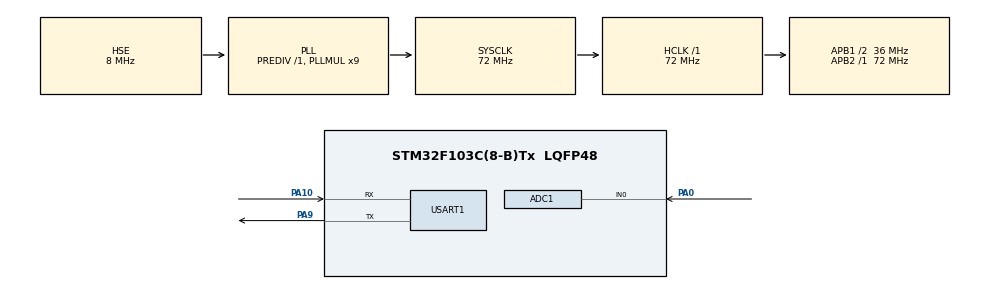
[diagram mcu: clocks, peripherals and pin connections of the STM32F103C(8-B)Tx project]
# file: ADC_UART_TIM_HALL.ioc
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ADC1.Channel-1\#ChannelRegularConversion=ADC_CHANNEL_0
ADC1.ExternalTrigConv=ADC_EXTERNALTRIGCONV_T1_CC1
ADC1.NbrOfConversionFlag=1
ADC1.Rank-1\#ChannelRegularConversion=1
ADC1.SamplingTime-1\#ChannelRegularConversion=ADC_SAMPLETIME_1CYCLE_5
ADC1.master=1
Mcu.Family=STM32F1
Mcu.Name=STM32F103C(8-B)Tx
Mcu.Package=LQFP48
NVIC.ADC1_2_IRQn=true\:0\:0\:false\:false\:true\:true\:true
NVIC.PriorityGroup=NVIC_PRIORITYGROUP_4
NVIC.TIM1_UP_IRQn=true\:0\:0\:false\:false\:true\:true\:true
NVIC.USART1_IRQn=true\:0\:0\:false\:false\:true\:true\:true
PA0-WKUP.Signal=ADCx_IN0
PA10.Mode=Asynchronous
PA10.Signal=USART1_RX
PA13.Mode=Serial_Wire
PA13.Signal=SYS_JTMS-SWDIO
PA14.Mode=Serial_Wire
PA14.Signal=SYS_JTCK-SWCLK
PA9.Mode=Asynchronous
PA9.Signal=USART1_TX
PD0-OSC_IN.Mode=HSE-External-Oscillator
PD0-OSC_IN.Signal=RCC_OSC_IN
PD1-OSC_OUT.Mode=HSE-External-Oscillator
PD1-OSC_OUT.Signal=RCC_OSC_OUT
ProjectManager.HeapSize=0x200
ProjectManager.StackSize=0x400
ProjectManager.TargetToolchain=STM32CubeIDE
RCC.ADCPresc=RCC_ADCPCLK2_DIV6
RCC.AHBFreq_Value=72000000
RCC.APB1CLKDivider=RCC_HCLK_DIV2
RCC.APB1Freq_Value=36000000
RCC.APB1TimFreq_Value=72000000
RCC.APB2Freq_Value=72000000
RCC.APB2TimFreq_Value=72000000
RCC.HCLKFreq_Value=72000000
RCC.PLLMUL=RCC_PLL_MUL9
RCC.PLLSourceVirtual=RCC_PLLSOURCE_HSE
RCC.SYSCLKFreq_VALUE=72000000
RCC.SYSCLKSource=RCC_SYSCLKSOURCE_PLLCLK
RCC.USBFreq_Value=72000000
SH.ADCx_IN0.0=ADC1_IN0,IN0
TIM1.Channel-Output\ Compare1\ No\ Output=TIM_CHANNEL_1
TIM1.OCMode_1=TIM_OCMODE_TOGGLE
TIM1.Period=7156
TIM1.Prescaler=0
TIM1.TIM_MasterOutputTrigger=TIM_TRGO_UPDATE
USART1.VirtualMode=VM_ASYNC
VP_TIM1_VS_ClockSourceINT.Mode=Internal
VP_TIM1_VS_ClockSourceITR.Mode=TriggerSource_ITR0
VP_TIM1_VS_no_output1.Mode=Output Compare1 No Output
board=custom

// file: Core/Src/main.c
/* USER CODE BEGIN Header */
/**
  ******************************************************************************
  * @file           : main.c
  * @brief          : Main program body
  ******************************************************************************
  * @attention
  *
  * <h2><center>&copy; Copyright (c) 2021 STMicroelectronics.
  * All rights reserved.</center></h2>
  *
  * This software component is licensed by ST under BSD 3-Clause license,
  * the "License"; You may not use this file except in compliance with the
  * License. You may obtain a copy of the License at:
  *                        opensource.org/licenses/BSD-3-Clause
  *
  ******************************************************************************
  */
/* USER CODE END Header */
#include "main.h"

/* USER CODE BEGIN Includes */
#include "string.h"
#include <stdio.h>
/* USER CODE END Includes */

ADC_HandleTypeDef hadc1;

TIM_HandleTypeDef htim1;

UART_HandleTypeDef huart1;

/* USER CODE BEGIN PV */
#define _SIZE 6000

uint16_t size = 0;
uint16_t str[_SIZE] = {0,};

char trans_str[64] = {0,};
volatile uint16_t adc = 0;

int flag = 0;

/* USER CODE END PV */

void SystemClock_Config(void);
static void MX_GPIO_Init(void);
static void MX_TIM1_Init(void);
static void MX_USART1_UART_Init(void);
static void MX_ADC1_Init(void);

/* USER CODE BEGIN 0 */
void HAL_TIM_PeriodElapsedCallback(TIM_HandleTypeDef *htim)
{

}
void HAL_ADC_ConvCpltCallback(ADC_HandleTypeDef* hadc)
{
	if(flag == 0)
	{
		adc = HAL_ADC_GetValue(&hadc1);
		str[size] = adc;
		if(adc == 2048)
		{
			flag = 1;
		}
		else
		{
			snprintf(trans_str, 63, "%d\n", str[size]);
			HAL_UART_Transmit(&huart1, (uint8_t*)trans_str, strlen(trans_str), 1000);
			size++;
			adc = 0;
		}
	}
}
/* USER CODE END 0 */

int main(void)
{

  /* MCU Configuration--------------------------------------------------------*/

  /* Reset of all peripherals, Initializes the Flash interface and the Systick. */
  HAL_Init();

  /* Configure the system clock */
  SystemClock_Config();

  /* Initialize all configured peripherals */
  MX_GPIO_Init();
  MX_TIM1_Init();
  MX_USART1_UART_Init();
  MX_ADC1_Init();
  /* USER CODE BEGIN 2 */
  HAL_ADCEx_Calibration_Start(&hadc1);
  HAL_ADC_Start_IT(&hadc1);
  HAL_TIM_OC_Start(&htim1, TIM_CHANNEL_1);
  /* USER CODE END 2 */

  /* Infinite loop */
  /* USER CODE BEGIN WHILE */
  while (1)
  {
	  if(flag == 1)
	  {
		  for(uint16_t i = 0; i < _SIZE; i++)
		  {
			  snprintf(trans_str, 63, "ADC = %d\n", str[i]);
			  HAL_UART_Transmit(&huart1, (uint8_t*)trans_str, strlen(trans_str), 1000);
//			  flag = 0;
			  flag = 2;
		  }
	  }

    /* USER CODE END WHILE */

 }
}

void SystemClock_Config(void)
{
  RCC_OscInitTypeDef RCC_OscInitStruct = {0};
  RCC_ClkInitTypeDef RCC_ClkInitStruct = {0};
  RCC_PeriphCLKInitTypeDef PeriphClkInit = {0};

  /** Initializes the RCC Oscillators according to the specified parameters
  * in the RCC_OscInitTypeDef structure.
  */
  RCC_OscInitStruct.OscillatorType = RCC_OSCILLATORTYPE_HSE;
  RCC_OscInitStruct.HSEState = RCC_HSE_ON;
  RCC_OscInitStruct.HSEPredivValue = RCC_HSE_PREDIV_DIV1;
  RCC_OscInitStruct.HSIState = RCC_HSI_ON;
  RCC_OscInitStruct.PLL.PLLState = RCC_PLL_ON;
  RCC_OscInitStruct.PLL.PLLSource = RCC_PLLSOURCE_HSE;
  RCC_OscInitStruct.PLL.PLLMUL = RCC_PLL_MUL9;
  if (HAL_RCC_OscConfig(&RCC_OscInitStruct) != HAL_OK)
  {
    Error_Handler();
  }
  /** Initializes the CPU, AHB and APB buses clocks
  */
  RCC_ClkInitStruct.ClockType = RCC_CLOCKTYPE_HCLK|RCC_CLOCKTYPE_SYSCLK
                              |RCC_CLOCKTYPE_PCLK1|RCC_CLOCKTYPE_PCLK2;
  RCC_ClkInitStruct.SYSCLKSource = RCC_SYSCLKSOURCE_PLLCLK;
  RCC_ClkInitStruct.AHBCLKDivider = RCC_SYSCLK_DIV1;
  RCC_ClkInitStruct.APB1CLKDivider = RCC_HCLK_DIV2;
  RCC_ClkInitStruct.APB2CLKDivider = RCC_HCLK_DIV1;

  if (HAL_RCC_ClockConfig(&RCC_ClkInitStruct, FLASH_LATENCY_2) != HAL_OK)
  {
    Error_Handler();
  }
  PeriphClkInit.PeriphClockSelection = RCC_PERIPHCLK_ADC;
  PeriphClkInit.AdcClockSelection = RCC_ADCPCLK2_DIV6;
  if (HAL_RCCEx_PeriphCLKConfig(&PeriphClkInit) != HAL_OK)
  {
    Error_Handler();
  }
}

static void MX_ADC1_Init(void)
{

  ADC_ChannelConfTypeDef sConfig = {0};

  /** Common config
  */
  hadc1.Instance = ADC1;
  hadc1.Init.ScanConvMode = ADC_SCAN_DISABLE;
  hadc1.Init.ContinuousConvMode = DISABLE;
  hadc1.Init.DiscontinuousConvMode = DISABLE;
  hadc1.Init.ExternalTrigConv = ADC_EXTERNALTRIGCONV_T1_CC1;
  hadc1.Init.DataAlign = ADC_DATAALIGN_RIGHT;
  hadc1.Init.NbrOfConversion = 1;
  if (HAL_ADC_Init(&hadc1) != HAL_OK)
  {
    Error_Handler();
  }
  /** Configure Regular Channel
  */
  sConfig.Channel = ADC_CHANNEL_0;
  sConfig.Rank = ADC_REGULAR_RANK_1;
  sConfig.SamplingTime = ADC_SAMPLETIME_1CYCLE_5;
  if (HAL_ADC_ConfigChannel(&hadc1, &sConfig) != HAL_OK)
  {
    Error_Handler();
  }

}

static void MX_TIM1_Init(void)
{

  TIM_ClockConfigTypeDef sClockSourceConfig = {0};
  TIM_SlaveConfigTypeDef sSlaveConfig = {0};
  TIM_MasterConfigTypeDef sMasterConfig = {0};
  TIM_OC_InitTypeDef sConfigOC = {0};
  TIM_BreakDeadTimeConfigTypeDef sBreakDeadTimeConfig = {0};

  htim1.Instance = TIM1;
  htim1.Init.Prescaler = 0;
  htim1.Init.CounterMode = TIM_COUNTERMODE_UP;
  htim1.Init.Period = 7156;
  htim1.Init.ClockDivision = TIM_CLOCKDIVISION_DIV1;
  htim1.Init.RepetitionCounter = 0;
  htim1.Init.AutoReloadPreload = TIM_AUTORELOAD_PRELOAD_DISABLE;
  if (HAL_TIM_Base_Init(&htim1) != HAL_OK)
  {
    Error_Handler();
  }
  sClockSourceConfig.ClockSource = TIM_CLOCKSOURCE_INTERNAL;
  if (HAL_TIM_ConfigClockSource(&htim1, &sClockSourceConfig) != HAL_OK)
  {
    Error_Handler();
  }
  if (HAL_TIM_OC_Init(&htim1) != HAL_OK)
  {
    Error_Handler();
  }
  sSlaveConfig.SlaveMode = TIM_SLAVEMODE_DISABLE;
  sSlaveConfig.InputTrigger = TIM_TS_ITR0;
  if (HAL_TIM_SlaveConfigSynchro(&htim1, &sSlaveConfig) != HAL_OK)
  {
    Error_Handler();
  }
  sMasterConfig.MasterOutputTrigger = TIM_TRGO_UPDATE;
  sMasterConfig.MasterSlaveMode = TIM_MASTERSLAVEMODE_DISABLE;
  if (HAL_TIMEx_MasterConfigSynchronization(&htim1, &sMasterConfig) != HAL_OK)
  {
    Error_Handler();
  }
  sConfigOC.OCMode = TIM_OCMODE_TOGGLE;
  sConfigOC.Pulse = 0;
  sConfigOC.OCPolarity = TIM_OCPOLARITY_HIGH;
  sConfigOC.OCNPolarity = TIM_OCNPOLARITY_HIGH;
  sConfigOC.OCFastMode = TIM_OCFAST_DISABLE;
  sConfigOC.OCIdleState = TIM_OCIDLESTATE_RESET;
  sConfigOC.OCNIdleState = TIM_OCNIDLESTATE_RESET;
  if (HAL_TIM_OC_ConfigChannel(&htim1, &sConfigOC, TIM_CHANNEL_1) != HAL_OK)
  {
    Error_Handler();
  }
  sBreakDeadTimeConfig.OffStateRunMode = TIM_OSSR_DISABLE;
  sBreakDeadTimeConfig.OffStateIDLEMode = TIM_OSSI_DISABLE;
  sBreakDeadTimeConfig.LockLevel = TIM_LOCKLEVEL_OFF;
  sBreakDeadTimeConfig.DeadTime = 0;
  sBreakDeadTimeConfig.BreakState = TIM_BREAK_DISABLE;
  sBreakDeadTimeConfig.BreakPolarity = TIM_BREAKPOLARITY_HIGH;
  sBreakDeadTimeConfig.AutomaticOutput = TIM_AUTOMATICOUTPUT_DISABLE;
  if (HAL_TIMEx_ConfigBreakDeadTime(&htim1, &sBreakDeadTimeConfig) != HAL_OK)
  {
    Error_Handler();
  }

}

static void MX_USART1_UART_Init(void)
{

  huart1.Instance = USART1;
  huart1.Init.BaudRate = 115200;
  huart1.Init.WordLength = UART_WORDLENGTH_8B;
  huart1.Init.StopBits = UART_STOPBITS_1;
  huart1.Init.Parity = UART_PARITY_NONE;
  huart1.Init.Mode = UART_MODE_TX_RX;
  huart1.Init.HwFlowCtl = UART_HWCONTROL_NONE;
  huart1.Init.OverSampling = UART_OVERSAMPLING_16;
  if (HAL_UART_Init(&huart1) != HAL_OK)
  {
    Error_Handler();
  }

}

static void MX_GPIO_Init(void)
{

  /* GPIO Ports Clock Enable */
  __HAL_RCC_GPIOD_CLK_ENABLE();
  __HAL_RCC_GPIOA_CLK_ENABLE();

}

void Error_Handler(void)
{
  __disable_irq();
  while (1)
  {
  }
}

/************************ (C) COPYRIGHT STMicroelectronics *****END OF FILE****/
